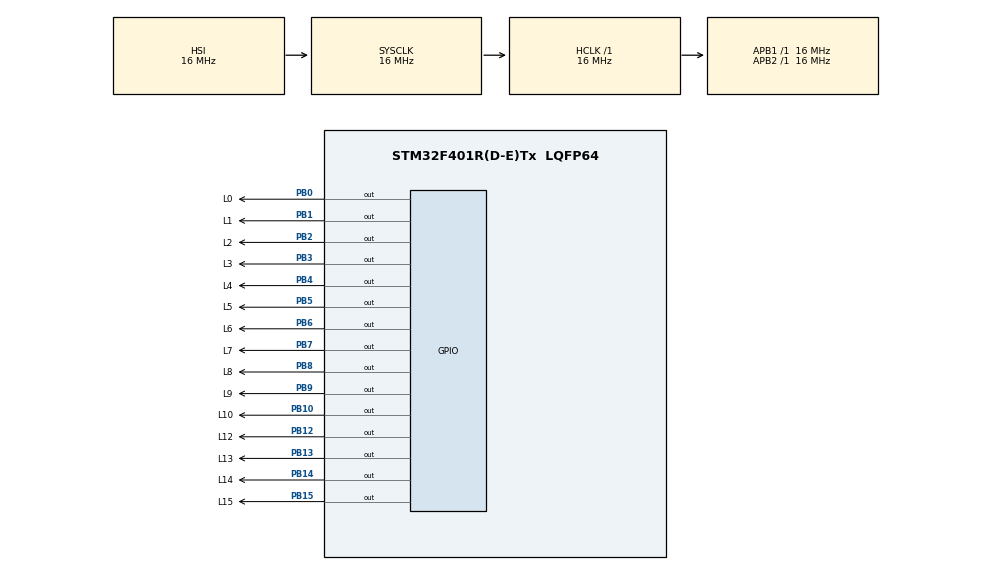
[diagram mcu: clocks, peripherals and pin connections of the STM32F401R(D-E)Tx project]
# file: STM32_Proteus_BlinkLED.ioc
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Mcu.Family=STM32F4
Mcu.Name=STM32F401R(D-E)Tx
Mcu.Package=LQFP64
NVIC.PriorityGroup=NVIC_PRIORITYGROUP_4
PB0.GPIO_Label=L0
PB0.Signal=GPIO_Output
PB1.GPIO_Label=L1
PB1.Signal=GPIO_Output
PB10.GPIO_Label=L10
PB10.Signal=GPIO_Output
PB12.GPIO_Label=L12
PB12.Signal=GPIO_Output
PB13.GPIO_Label=L13
PB13.Signal=GPIO_Output
PB14.GPIO_Label=L14
PB14.Signal=GPIO_Output
PB15.GPIO_Label=L15
PB15.Signal=GPIO_Output
PB2.GPIO_Label=L2
PB2.Signal=GPIO_Output
PB3.GPIO_Label=L3
PB3.Signal=GPIO_Output
PB4.GPIO_Label=L4
PB4.Signal=GPIO_Output
PB5.GPIO_Label=L5
PB5.Signal=GPIO_Output
PB6.GPIO_Label=L6
PB6.Signal=GPIO_Output
PB7.GPIO_Label=L7
PB7.Signal=GPIO_Output
PB8.GPIO_Label=L8
PB8.Signal=GPIO_Output
PB9.GPIO_Label=L9
PB9.Signal=GPIO_Output
PC14-OSC32_IN.Mode=LSE-External-Oscillator
PC14-OSC32_IN.Signal=RCC_OSC32_IN
PC15-OSC32_OUT.Mode=LSE-External-Oscillator
PC15-OSC32_OUT.Signal=RCC_OSC32_OUT
PH0\ -\ OSC_IN.Mode=HSE-External-Oscillator
PH0\ -\ OSC_IN.Signal=RCC_OSC_IN
PH1\ -\ OSC_OUT.Mode=HSE-External-Oscillator
PH1\ -\ OSC_OUT.Signal=RCC_OSC_OUT
ProjectManager.HeapSize=0x200
ProjectManager.StackSize=0x400
ProjectManager.TargetToolchain=STM32CubeIDE
RCC.AHBFreq_Value=16000000
RCC.APB1Freq_Value=16000000
RCC.APB2Freq_Value=16000000
RCC.CortexFreq_Value=16000000
RCC.HSE_VALUE=25000000
RCC.HSI_VALUE=16000000
RCC.SYSCLKFreq_VALUE=16000000
RCC.VCOOutputFreq_Value=192000000
board=custom

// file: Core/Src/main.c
/* USER CODE BEGIN Header */
/**
  ******************************************************************************
  * @file           : main.c
  * @brief          : Main program body
  ******************************************************************************
  * @attention
  *
  * Copyright (c) 2024 STMicroelectronics.
  * All rights reserved.
  *
  * This software is licensed under terms that can be found in the LICENSE file
  * in the root directory of this software component.
  * If no LICENSE file comes with this software, it is provided AS-IS.
  *
  ******************************************************************************
  */
/* USER CODE END Header */
#include "main.h"

/* USER CODE BEGIN Includes */
#include <string.h>
#include <stdio.h>
/* USER CODE END Includes */

/* USER CODE BEGIN PV */
uint16_t Pin[] = {L0_Pin,L1_Pin,L2_Pin,L3_Pin,L4_Pin,L5_Pin,L6_Pin,L7_Pin,L8_Pin,L9_Pin,L10_Pin,L12_Pin,L13_Pin,L14_Pin,L15_Pin};
char arr[20];
/* USER CODE END PV */

void SystemClock_Config(void);
static void MX_GPIO_Init(void);

int main(void)
{

  /* MCU Configuration--------------------------------------------------------*/

  /* Reset of all peripherals, Initializes the Flash interface and the Systick. */
  HAL_Init();

  /* Configure the system clock */
  SystemClock_Config();

  /* Initialize all configured peripherals */
  MX_GPIO_Init();

  /* Infinite loop */
  /* USER CODE BEGIN WHILE */
  while (1)
  {
	  for(uint8_t i=0;i<15;i++) {
		  HAL_GPIO_WritePin(GPIOB, Pin[i]	, GPIO_PIN_SET);
		  HAL_Delay(100);

	  }

	  for(uint8_t i=0;i<15;i++) {
		  HAL_GPIO_WritePin(GPIOB, Pin[i]	, GPIO_PIN_RESET);
		  HAL_Delay(100);

	  }
    /* USER CODE END WHILE */

  }
}

void SystemClock_Config(void)
{
  RCC_OscInitTypeDef RCC_OscInitStruct = {0};
  RCC_ClkInitTypeDef RCC_ClkInitStruct = {0};

  /** Configure the main internal regulator output voltage
  */
  __HAL_RCC_PWR_CLK_ENABLE();
  __HAL_PWR_VOLTAGESCALING_CONFIG(PWR_REGULATOR_VOLTAGE_SCALE2);

  /** Initializes the RCC Oscillators according to the specified parameters
  * in the RCC_OscInitTypeDef structure.
  */
  RCC_OscInitStruct.OscillatorType = RCC_OSCILLATORTYPE_HSI;
  RCC_OscInitStruct.HSIState = RCC_HSI_ON;
  RCC_OscInitStruct.HSICalibrationValue = RCC_HSICALIBRATION_DEFAULT;
  RCC_OscInitStruct.PLL.PLLState = RCC_PLL_NONE;
  if (HAL_RCC_OscConfig(&RCC_OscInitStruct) != HAL_OK)
  {
    Error_Handler();
  }

  /** Initializes the CPU, AHB and APB buses clocks
  */
  RCC_ClkInitStruct.ClockType = RCC_CLOCKTYPE_HCLK|RCC_CLOCKTYPE_SYSCLK
                              |RCC_CLOCKTYPE_PCLK1|RCC_CLOCKTYPE_PCLK2;
  RCC_ClkInitStruct.SYSCLKSource = RCC_SYSCLKSOURCE_HSI;
  RCC_ClkInitStruct.AHBCLKDivider = RCC_SYSCLK_DIV1;
  RCC_ClkInitStruct.APB1CLKDivider = RCC_HCLK_DIV1;
  RCC_ClkInitStruct.APB2CLKDivider = RCC_HCLK_DIV1;

  if (HAL_RCC_ClockConfig(&RCC_ClkInitStruct, FLASH_LATENCY_0) != HAL_OK)
  {
    Error_Handler();
  }
}

static void MX_GPIO_Init(void)
{
  GPIO_InitTypeDef GPIO_InitStruct = {0};

  /* GPIO Ports Clock Enable */
  __HAL_RCC_GPIOC_CLK_ENABLE();
  __HAL_RCC_GPIOH_CLK_ENABLE();
  __HAL_RCC_GPIOB_CLK_ENABLE();

  /*Configure GPIO pin Output Level */
  HAL_GPIO_WritePin(GPIOB, L0_Pin|L1_Pin|L2_Pin|L10_Pin
                          |L12_Pin|L13_Pin|L14_Pin|L15_Pin
                          |L3_Pin|L4_Pin|L5_Pin|L6_Pin
                          |L7_Pin|L8_Pin|L9_Pin, GPIO_PIN_RESET);

  /*Configure GPIO pins : L0_Pin L1_Pin L2_Pin L10_Pin
                           L12_Pin L13_Pin L14_Pin L15_Pin
                           L3_Pin L4_Pin L5_Pin L6_Pin
                           L7_Pin L8_Pin L9_Pin */
  GPIO_InitStruct.Pin = L0_Pin|L1_Pin|L2_Pin|L10_Pin
                          |L12_Pin|L13_Pin|L14_Pin|L15_Pin
                          |L3_Pin|L4_Pin|L5_Pin|L6_Pin
                          |L7_Pin|L8_Pin|L9_Pin;
  GPIO_InitStruct.Mode = GPIO_MODE_OUTPUT_PP;
  GPIO_InitStruct.Pull = GPIO_NOPULL;
  GPIO_InitStruct.Speed = GPIO_SPEED_FREQ_LOW;
  HAL_GPIO_Init(GPIOB, &GPIO_InitStruct);

}

void Error_Handler(void)
{
  __disable_irq();
  while (1)
  {
  }
}
